AUTOSAR XML (schema 00049)
package /Application/DltConfig
  dlt log channel to process mapping DltLogChannelToProcessMapping_SOA_SmartFilm_TO_SOA_SmartFilm: dlt-log-channel=SOA_SmartFilm, process=SOA_SmartFilm
package /Application/Executable
  executable SOA_SmartFilm: category=APPLICATION_LEVEL, logging-behavior=USES-LOGGING, reporting-behavior=REPORTS-EXECUTION-STATE, version=1.0.0
    root sw component prototype AA: application-type=SOA_SmartFilm
package /Application/Manifest
  service instance to port prototype mapping SOA_SmartFilm_AA_PPort_SOA_SmartFilm: port-prototype=AA.PPort_SOA_SmartFilm, process=SOA_SmartFilm, service-instance=Provider_SoaSmartFilm
  service instance to port prototype mapping SOA_SmartFilm_AA_RPort_Zone1VehicleInfo: port-prototype=AA.RPort_Zone1VehicleInfo, process=SOA_SmartFilm, service-instance=Consumer_SoaSmartFilm_VehicleInfo
  service instance to port prototype mapping SOA_SmartFilm_AA_RPort_Zone5_SmtFilm: port-prototype=AA.RPort_Zone5_SmtFilm, process=SOA_SmartFilm, service-instance=Consumer_Zone5SmtFilm
package /Application/Package/SOA_SmartFilm/SoftwareCluster_1_0_0
  software cluster SOA_SmartFilm_SoftwareCluster: category=APPLICATION_LAYER, contained-ar-element=SOA_SmartFilm, contained-package-element=[SOA_SmartFilm_AA_PPort_SOA_SmartFilm, SOA_SmartFilm_AA_RPort_Zone1VehicleInfo, SOA_SmartFilm_AA_RPort_Zone5_SmtFilm], contained-process=SOA_SmartFilm, vendor-id=79, vendor-signature=ParaCertificate, version=1.0.0
package /Application/Package/SOA_SmartFilm/SoftwareCluster_1_0_1
  software cluster SOA_SmartFilm_SoftwareCluster: category=APPLICATION_LAYER, contained-ar-element=SOA_SmartFilm, contained-package-element=[SOA_SmartFilm_AA_PPort_SOA_SmartFilm, SOA_SmartFilm_AA_RPort_Zone1VehicleInfo, SOA_SmartFilm_AA_RPort_Zone5_SmtFilm], contained-process=SOA_SmartFilm, vendor-id=79, vendor-signature=ParaCertificate, version=1.0.1
package /Application/Package/SOA_SmartFilm/SoftwareCluster_1_0_2
  software cluster SOA_SmartFilm_SoftwareCluster: category=APPLICATION_LAYER, contained-ar-element=SOA_SmartFilm, contained-package-element=[SOA_SmartFilm_AA_PPort_SOA_SmartFilm, SOA_SmartFilm_AA_RPort_Zone1VehicleInfo, SOA_SmartFilm_AA_RPort_Zone5_SmtFilm], contained-process=SOA_SmartFilm, vendor-id=79, vendor-signature=ParaCertificate, version=1.0.2
package /Application/Package/SOA_SmartFilm/SoftwarePackage
  software package SOA_SmartFilm_InstallSoftwarePackage_1_0_0: action-type=INSTALL, compressed-software-package-size=0, maximum-supported-ucm-version=1.0.0, minimum-supported-ucm-version=1.0.0, packager-id=79, packager-signature=ParaCertificate, post-verification-reboot=false, pre-activate=SC.Off, pre-activation-reboot=false, software-cluster=SoftwareCluster_1_0_0/SOA_SmartFilm_SoftwareCluster, uncompressed-software-cluster-size=0, verify=SC.Verify
  software package SOA_SmartFilm_RemoveSoftwarePackage_1_0_2: action-type=REMOVE, compressed-software-package-size=0, maximum-supported-ucm-version=1.0.0, minimum-supported-ucm-version=1.0.0, packager-id=79, packager-signature=ParaCertificate, post-verification-reboot=false, pre-activate=SC.Off, pre-activation-reboot=false, software-cluster=SoftwareCluster_1_0_2/SOA_SmartFilm_SoftwareCluster, uncompressed-software-cluster-size=0, verify=SC.Verify
  software package SOA_SmartFilm_UpdateSoftwarePackage_1_0_1: action-type=UPDATE, compressed-software-package-size=0, maximum-supported-ucm-version=1.0.0, minimum-supported-ucm-version=1.0.0, packager-id=79, packager-signature=ParaCertificate, post-verification-reboot=false, pre-activate=SC.Off, pre-activation-reboot=false, software-cluster=SoftwareCluster_1_0_1/SOA_SmartFilm_SoftwareCluster, uncompressed-software-cluster-size=0, verify=SC.Verify
package /Application/Package/SOA_SmartFilm/VehiclePackage
  vehicle package SOA_SmartFilm_InstallVehiclePackage_1_0_0: vehicle-driver-notification{approval-required=true, notification-state=PROCESS}, packager-signature=ParaCertificate
    rollout-qualifications:
      vehicle rollout step RolloutQualification0
        ucm-processings:
          ucm step UcmProcessing0: ucm=SOA_SmartFilm_InstallVehiclePackage_1_0_0/EEVP_UCM
            software package step SoftwarePackageStep0: process=SOA_SmartFilm_InstallSoftwarePackage_1_0_0, transfers=software-package-storing={storing=UCM, transfer=SOA_SmartFilm_InstallSoftwarePackage_1_0_0}
    ucm description EEVP_UCM: identifier=EEVP_UCM
  vehicle package SOA_SmartFilm_RemoveVehiclePackage_1_0_2: vehicle-driver-notification{approval-required=true, notification-state=PROCESS}, packager-signature=ParaCertificate
    rollout-qualifications:
      vehicle rollout step RolloutQualification0
        ucm-processings:
          ucm step UcmProcessing0
            software package step SoftwarePackageStep0: process=SOA_SmartFilm_RemoveSoftwarePackage_1_0_2, transfers=software-package-storing={storing=UCM, transfer=SOA_SmartFilm_RemoveSoftwarePackage_1_0_2}
    ucm description EEVP_UCM: identifier=EEVP_UCM
  vehicle package SOA_SmartFilm_UpdateVehiclePackage_1_0_1: vehicle-driver-notification{approval-required=true, notification-state=PROCESS}, packager-signature=ParaCertificate
    rollout-qualifications:
      vehicle rollout step RolloutQualification0
        ucm-processings:
          ucm step UcmProcessing0: ucm=SOA_SmartFilm_UpdateVehiclePackage_1_0_1/EEVP_UCM
            software package step SoftwarePackageStep0: process=SOA_SmartFilm_UpdateSoftwarePackage_1_0_1, transfers=software-package-storing={storing=UCM, transfer=SOA_SmartFilm_UpdateSoftwarePackage_1_0_1}
    ucm description EEVP_UCM: identifier=EEVP_UCM
package /Application/Process
  process SOA_SmartFilm: executable=SOA_SmartFilm, state-dependent-startup-config{function-group-state=[SC.On, SC.Verify], resource-group=DefaultResourceGroup, startup-config=SOA}
    process state machine SOA_SmartFilm: type=ProcessState
package /Application/SwComponent
  adaptive application sw component type Application35
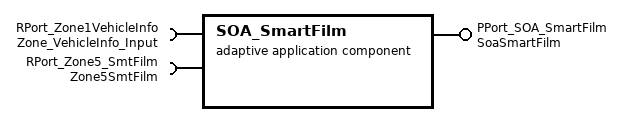
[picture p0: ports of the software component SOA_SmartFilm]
  adaptive application sw component type SOA_SmartFilm
    provide port PPort_SOA_SmartFilm: provided-interface=SoaSmartFilm
    require port RPort_Zone1VehicleInfo: required-interface=Zone_VehicleInfo_Input
    require port RPort_Zone5_SmtFilm: required-interface=Zone5SmtFilm
